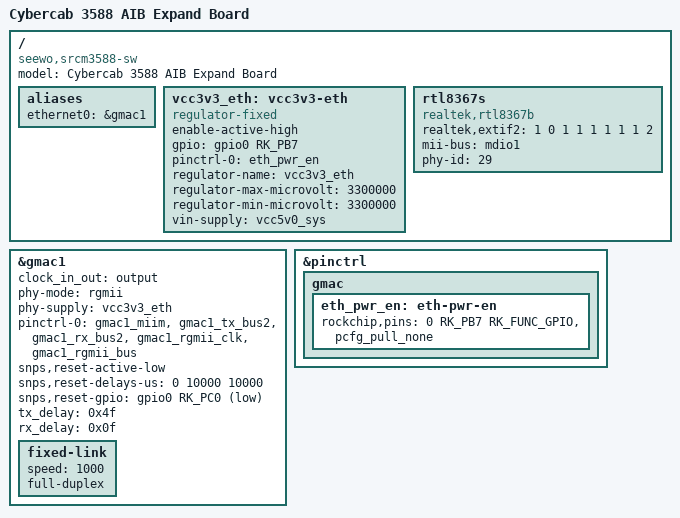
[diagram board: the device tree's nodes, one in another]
// SPDX-License-Identifier: (GPL-2.0+ OR MIT)

/dts-v1/;
#include "rk3588-srcm3588-io.dts"

/ {
	model = "Cybercab 3588 AIB Expand Board";
	compatible = "seewo,srcm3588-sw", "rockchip,rk3588";

	aliases {
		ethernet0 = &gmac1;
	};

	vcc3v3_eth: vcc3v3-eth {
		compatible = "regulator-fixed";
		enable-active-high;
		gpio = <&gpio0 RK_PB7 GPIO_ACTIVE_HIGH>;
		pinctrl-names = "default";
		pinctrl-0 = <&eth_pwr_en>;
		regulator-name = "vcc3v3_eth";
		regulator-max-microvolt = <3300000>;
		regulator-min-microvolt = <3300000>;
		vin-supply = <&vcc5v0_sys>;
	};

	rtl8367s {
		compatible = "realtek,rtl8367b";
		realtek,extif2 = <1 0 1 1 1 1 1 1 2>;
		mii-bus = <&mdio1>;
		phy-id = <29>;
	};
};

/*
 * The stmmac driver used by rk3588 has a bug in VLAN.
 * Instead of hacking it, use the legacy switch driver
 * first. Obviously this is not a DSA driver bug.
 */
&gmac1 {
	clock_in_out = "output";
	phy-mode = "rgmii";
	phy-supply = <&vcc3v3_eth>;
	pinctrl-0 = <&gmac1_miim
		     &gmac1_tx_bus2
		     &gmac1_rx_bus2
		     &gmac1_rgmii_clk
		     &gmac1_rgmii_bus>;
	pinctrl-names = "default";
	snps,reset-active-low;
	snps,reset-delays-us = <0 10000 10000>;
	snps,reset-gpio = <&gpio0 RK_PC0 GPIO_ACTIVE_LOW>;
	tx_delay = <0x4f>;
	rx_delay = <0x0f>;
	status = "okay";

	fixed-link {
		speed = <1000>;
		full-duplex;
	};
};

&pinctrl {
	gmac {
		eth_pwr_en: eth-pwr-en {
			rockchip,pins = <0 RK_PB7 RK_FUNC_GPIO &pcfg_pull_none>;
		};
	};
};
